# AM13E230x register map
Vendor: Texas Instruments; File version: Revised: 2025-12-26 17:30:06
CPU: CM33 r0p0, little endian, MPU, FPU, 4 interrupt priority bits
Registers are 32-bit, read-write, reset 0x0 unless marked. A register's access mark holds for its fields unless they carry their own. Offsets are from the block's base; [hi:lo] are bit positions; lines under a group give offsets from that group; {n}, {i} and the like mark numbered series; 'fields as' and 'values as' point back to an identical list.

## MCAN — PERIPHERALREGION
Base 0x40110000
{0x6004+8i} PINCM[{i}] (i=0..0) group
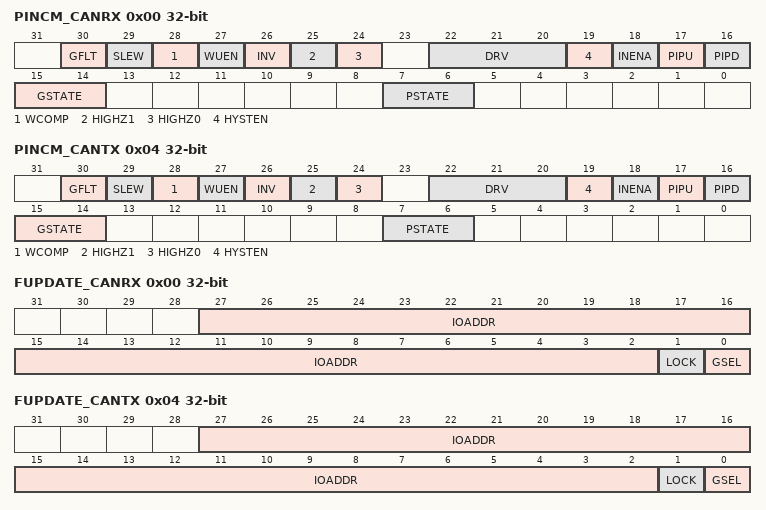
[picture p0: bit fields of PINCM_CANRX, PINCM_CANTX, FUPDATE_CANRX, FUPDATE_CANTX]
  0x00 PINCM_CANRX — CAN RX IO
    [30] GFLT — Glitch Filter Enable
      0=DISABLE (No internal glitch filter); 1=ENABLE (Use internal glitch filter)
    [29] SLEW — Reserved Slew Rate Control
      0=DISABLE (No Slew Rate Control); 1=ENABLE (Use Slew Rate Control)
    [28] WCOMP — Wake up compare value
      0=MATCH_ZERO (Match 0 will wake); 1=MATCH_ONE (Match 1 will wake)
    [27] WUEN — Wake up enable
      0=NO_WAKEUP (Wake up not enabled); 1=WAKEUP (Wake up enabled)
    [26] INV — Invert digital input/output relative to peripheral/GPIO
      0=NO_CHNG (Input and output are non-inverted); 1=CHNG (Input and output are inverted)
    [25] HIGHZ1 — High-Z instead of high output
      0=DRV_HIGH (Pin can be driven high); 1=DRV_HIZ (Pin is tri-stated instead of driven high)
    [24] HIGHZ0 — High-Z instead of low output
      0=DRV_LOW (Pin can be driven low); 1=DRV_HIZ (Pin is tri-stated instead of driven low)
    [22:20] DRV — Drive strength options
      0=STRENGTH_0 (Lowest drive strength); {v}=STRENGTH_{v} (Drive strength {v+1}/8) (v=1..6); 7=STRENGTH_7 (Highest drive strength)
    [19] HYSTEN — Hysteresis enable
      0=DIS_HYST (No hysteresis); 1=EN_HYST (Hysteresis on)
    [18] INENA — Input enable
      0=INP_DISABLE (Inputs 0 to connected core); 1=INP_ENABLE (Inputs IO pad value to connected core)
    [17] PIPU — Pull up enable
      0=NO_PULL_UP; 1=PULL_UP
    [16] PIPD — Pull down enable
      0=NO_PULL_DOWN; 1=PULL_DOWN
    [15:14] GSTATE — GPIO Channel State
      0=UNASSIGNED (G-Channel is in Unassigned State); 1=HANDOVER (G-Channel is in Handover State); 2=CONC_NOT_LOCKED (G-Channel is in Connected State and not Locked (That is F field is allowed to change without going back through Unassigned state)); 3=CONC_LOCKED (G-Channel is in Connected State and Locked (That is F field is not allowed to change to a different non-Zero value until both G and P channels go to Unassigned))
    [7:6] PSTATE — Peripheral-Analog Channel State
      0=UNASSIGNED (P-Channel is in Unassigned State); 1=HANDOVER (P-Channel is in Handover State); 2=CONC_NOT_LOCKED (P-Channel is in Connected State and not Locked (That is F field is allowed to change without going back through Unassigned state)); 3=CONC_LOCKED (P-Channel is in Connected State and Locked (That is F field is not allowed to change to a different non-Zero value until both G and P channels go to Unassigned))
  0x04 PINCM_CANTX — CAN TX IO
    fields as PINCM[0].PINCM_CANRX
{0x6204+8i} FUPDATE[{i}] (i=0..0) group
  0x00 FUPDATE_CANRX — FUPDATE version of CANRX
    [27:2] IOADDR wo — IO Address. This is the address that corresponds to the SOC address[27:2] of the module IP instance specific IO signal in the Full Write subregion of the pinmux subregion.
    [1] LOCK wo — Sets lock bit
      0=NOEFFECT (Writing this value has no effect); 1=LOCK (Set channel lock bit)
    [0] GSEL wo — GPIO channel Select 0: Select the P-Channel for the F update 1: Select the G-Channel for the F update
      0=PCHAN (Select the P-Channel for the F update); 1=GCHAN (Select the G-Channel for the F update)
  0x04 FUPDATE_CANTX — FUPDATE version of CANTX
    fields as FUPDATE[0].FUPDATE_CANRX
0x6480 CPU_CONNECT_0 — CPU Connect
0x6800 PWREN — Power enable
  [0] ENABLE — Power Enable
    0=DISABLE (Disable Power); 1=ENABLE (Enable Power)
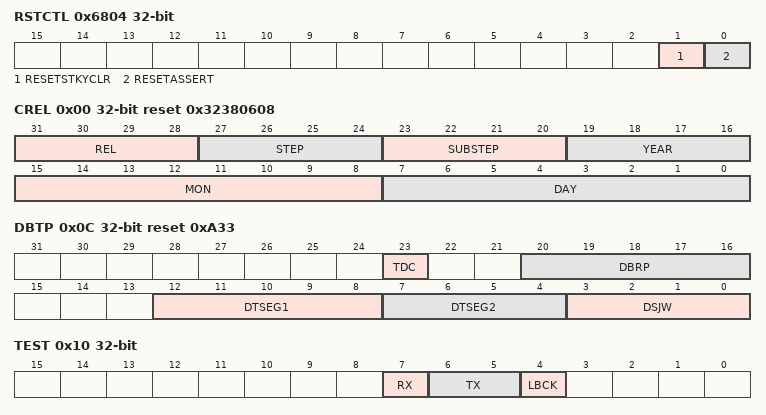
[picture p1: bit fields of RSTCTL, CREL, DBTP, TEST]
0x6804 RSTCTL wo — Reset Control
  [1] RESETSTKYCLR — Reset sticky bit clear
    0=NOP (Writing 0 has no effect); 1=CLR (Clear reset sticky bit)
  [0] RESETASSERT — Reset assertion to the peripheral
    0=NOP (Writing 0 has no effect); 1=ASSERT (Assert reset)
0x6814 STAT ro — Status Register
  [16] RESETSTKY — Reset sticky bit
    0=NORES (The peripheral has not been reset since this bit was last cleared by RESETSTKYCLR in the RSTCTL register); 1=RESET (The peripheral was reset since the last bit clear)
{0x7000+0xFC*i} MCAN[{i}] (i=0..0) group
  0x00 CREL ro reset 0x32380608 — MCAN Core Release Register
    [31:28] REL — Core Release
    [27:24] STEP — Step of Core Release
    [23:20] SUBSTEP — Sub-Step of Core Release
    [19:16] YEAR — Time Stamp Year
    [15:8] MON — Time Stamp Month
    [7:0] DAY — Time Stamp Day
  0x04 ENDN ro reset 0x87654321 — MCAN Endian Register
  0x0C DBTP reset 0xA33 — MCAN Data Bit Timing and Prescaler Register
    [23] TDC — Transmitter Delay Compensation
    [20:16] DBRP — Data Bit Rate Prescaler
    [12:8] DTSEG1 — Data Time Segment Before Sample Point
    [7:4] DTSEG2 — Data Time Segment After Sample Point
    [3:0] DSJW — Data Resynchronization Jump Width
  0x10 TEST (reset mask 0xFFFFFF7F) — MCAN Test Register
    [7] RX ro — Receive Pin
      0=DOMINANT (The CAN bus is dominant (CAN RX pin = '0')); 1=RECESSIVE (The CAN bus is recessive (CAN RX pin = '1'))
    [6:5] TX — Control of Transmit Pin
    [4] LBCK — Loop Back Mode
      0=DISABLE (Reset value, Loop Back Mode is disabled); 1=ENABLE (Loop Back Mode is enabled)
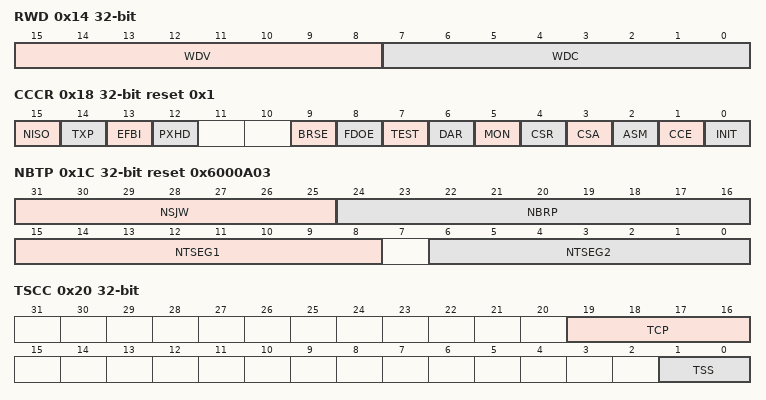
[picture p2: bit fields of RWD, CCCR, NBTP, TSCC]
  0x14 RWD — MCAN RAM Watchdog
    [15:8] WDV ro — Watchdog Value
    [7:0] WDC — Watchdog Configuration
  0x18 CCCR reset 0x1 — MCAN CC Control Register
    [15] NISO — Non-ISO Operation
    [14] TXP — Transmit Pause
    [13] EFBI — Edge Filtering During Bus Integration
    [12] PXHD — Protocol Exception Handling Disable
    [9] BRSE — Bit Rate Switch Enable
    [8] FDOE — Flexible Datarate Operation Enable
    [7] TEST — Test Mode Enable
    [6] DAR — Disable Automatic Retransmission
    [5] MON — Bus Monitoring Mode
    [4] CSR — Clock Stop Request
    [3] CSA ro — Clock Stop Acknowledge
    [2] ASM — Restricted Operation Mode
    [1] CCE — Configuration Change Enable
    [0] INIT — Initialization
  0x1C NBTP reset 0x6000A03 — MCAN Nominal Bit Timing and Prescaler Register
    [31:25] NSJW — Nominal (Re)Synchronization Jump Width
    [24:16] NBRP — Nominal Bit Rate Prescaler
    [15:8] NTSEG1 — Nominal Time Segment Before Sample Point
    [6:0] NTSEG2 — Nominal Time Segment After Sample Point
  0x20 TSCC — MCAN Timestamp Counter Configuration
    [19:16] TCP — Timestamp Counter Prescaler
    [1:0] TSS — Timestamp Select
  0x24 TSCV — MCAN Timestamp Counter Value
    [15:0] TSC — Timestamp Counter
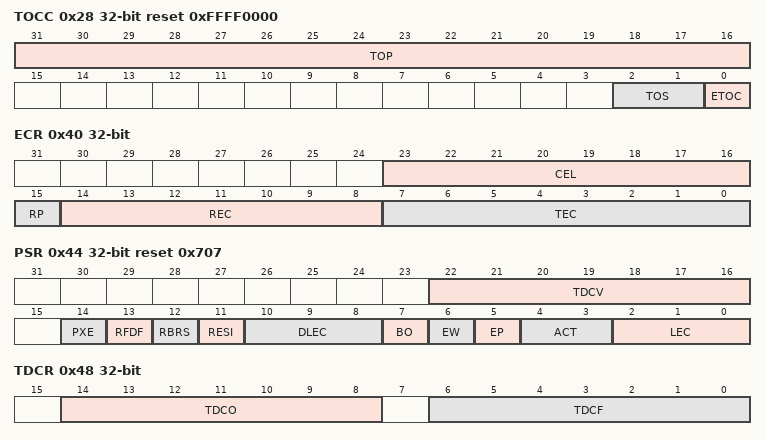
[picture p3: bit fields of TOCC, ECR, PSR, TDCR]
  0x28 TOCC reset 0xFFFF0000 — MCAN Timeout Counter Configuration
    [31:16] TOP — Timeout Period
    [2:1] TOS — Timeout Select
    [0] ETOC — Enable Timeout Counter
  0x2C TOCV reset 0xFFFF — MCAN Timeout Counter Value
    [15:0] TOC — Timeout Counter
  0x40 ECR ro — MCAN Error Counter Register
    [23:16] CEL — CAN Error Logging
    [15] RP — Receive Error Passive
    [14:8] REC — Receive Error Counter
    [7:0] TEC — Transmit Error Counter
  0x44 PSR ro reset 0x707 — MCAN Protocol Status Register
    [22:16] TDCV — Transmitter Delay Compensation Value
    [14] PXE — Protocol Exception Event
    [13] RFDF — Received a CAN FD Message
    [12] RBRS — BRS Flag of Last Received CAN FD Message
    [11] RESI — ESI Flag of Last Received CAN FD Message
    [10:8] DLEC — Data Phase Last Error Code
    [7] BO — Bus_Off Status
    [6] EW — Warning Status
    [5] EP — Error Passive
    [4:3] ACT — Node Activity
    [2:0] LEC — Last Error Code
  0x48 TDCR — MCAN Transmitter Delay Compensation Register
    [14:8] TDCO — Transmitter Delay Compensation Offset
    [6:0] TDCF — Transmitter Delay Compensation Filter Window Length
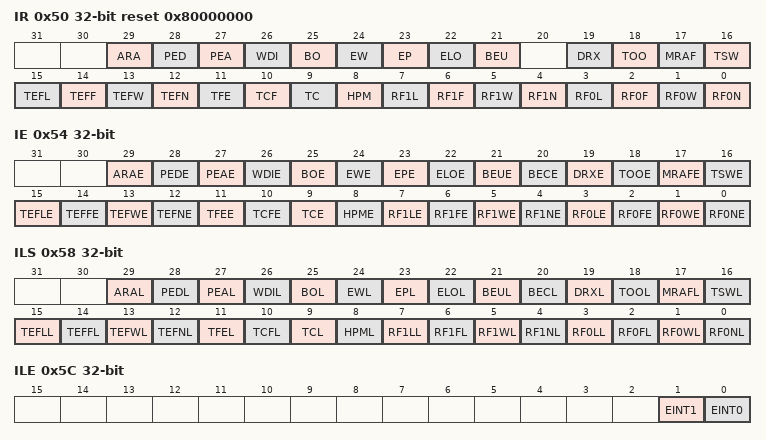
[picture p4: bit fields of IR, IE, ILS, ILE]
  0x50 IR reset 0x80000000 — MCAN Interrupt Register
    [29] ARA — Access to Reserved Address
    [28] PED — Protocol Error in Data Phase
    [27] PEA — Protocol Error in Arbitration Phase
    [26] WDI — Watchdog Interrupt
    [25] BO — Bus_Off Status
    [24] EW — Warning Status
    [23] EP — Error Passive
    [22] ELO — Error Logging Overflow
    [21] BEU — Bit Error Uncorrected
    [19] DRX — Message Stored to Dedicated Rx Buffer
    [18] TOO — Timeout Occurred
    [17] MRAF — Message RAM Access Failure
    [16] TSW — Timestamp Wraparound
    [15] TEFL — Tx Event FIFO Element Lost
    [14] TEFF — Tx Event FIFO Full
    [13] TEFW — Tx Event FIFO Watermark Reached
    [12] TEFN — Tx Event FIFO New Entry
    [11] TFE — Tx FIFO Empty
    [10] TCF — Transmission Cancellation Finished
    [9] TC — Transmission Completed
    [8] HPM — High Priority Message
    [7] RF1L — Rx FIFO 1 Message Lost
    [6] RF1F — Rx FIFO 1 Full
    [5] RF1W — Rx FIFO 1 Watermark Reached
    [4] RF1N — Rx FIFO 1 New Message
    [3] RF0L — Rx FIFO 0 Message Lost
    [2] RF0F — Rx FIFO 0 Full
    [1] RF0W — Rx FIFO 0 Watermark Reached
    [0] RF0N — Rx FIFO 0 New Message
  0x54 IE — MCAN Interrupt Enable
    [29] ARAE — Access to Reserved Address Enable
    [28] PEDE — Protocol Error in Data Phase Enable
    [27] PEAE — Protocol Error in Arbitration Phase Enable
    [26] WDIE — Watchdog Interrupt Enable
    [25] BOE — Bus_Off Status Enable
    [24] EWE — Warning Status Enable
    [23] EPE — Error Passive Enable
    [22] ELOE — Error Logging Overflow Enable
    [21] BEUE — Bit Error Uncorrected Enable
    [20] BECE — Bit Error Corrected Enable
    [19] DRXE — Message Stored to Dedicated Rx Buffer Enable
    [18] TOOE — Timeout Occurred Enable
    [17] MRAFE — Message RAM Access Failure Enable
    [16] TSWE — Timestamp Wraparound Enable
    [15] TEFLE — Tx Event FIFO Element Lost Enable
    [14] TEFFE — Tx Event FIFO Full Enable
    [13] TEFWE — Tx Event FIFO Watermark Reached Enable
    [12] TEFNE — Tx Event FIFO New Entry Enable
    [11] TFEE — Tx FIFO Empty Enable
    [10] TCFE — Transmission Cancellation Finished Enable
    [9] TCE — Transmission Completed Enable
    [8] HPME — High Priority Message Enable
    [7] RF1LE — Rx FIFO 1 Message Lost Enable
    [6] RF1FE — Rx FIFO 1 Full Enable
    [5] RF1WE — Rx FIFO 1 Watermark Reached Enable
    [4] RF1NE — Rx FIFO 1 New Message Enable
    [3] RF0LE — Rx FIFO 0 Message Lost Enable
    [2] RF0FE — Rx FIFO 0 Full Enable
    [1] RF0WE — Rx FIFO 0 Watermark Reached Enable
    [0] RF0NE — Rx FIFO 0 New Message Enable
  0x58 ILS — MCAN Interrupt Line Select
    [29] ARAL — Access to Reserved Address Line
    [28] PEDL — Protocol Error in Data Phase Line
    [27] PEAL — Protocol Error in Arbitration Phase Line
    [26] WDIL — Watchdog Interrupt Line
    [25] BOL — Bus_Off Status Line
    [24] EWL — Warning Status Line
    [23] EPL — Error Passive Line
    [22] ELOL — Error Logging Overflow Line
    [21] BEUL — Bit Error Uncorrected Line
    [20] BECL — Bit Error Corrected Line
    [19] DRXL — Message Stored to Dedicated Rx Buffer Line
    [18] TOOL — Timeout Occurred Line
    [17] MRAFL — Message RAM Access Failure Line
    [16] TSWL — Timestamp Wraparound Line
    [15] TEFLL — Tx Event FIFO Element Lost Line
    [14] TEFFL — Tx Event FIFO Full Line
    [13] TEFWL — Tx Event FIFO Watermark Reached Line
    [12] TEFNL — Tx Event FIFO New Entry Line
    [11] TFEL — Tx FIFO Empty Line
    [10] TCFL — Transmission Cancellation Finished Line
    [9] TCL — Transmission Completed Line
    [8] HPML — High Priority Message Line
    [7] RF1LL — Rx FIFO 1 Message Lost Line
    [6] RF1FL — Rx FIFO 1 Full Line
    [5] RF1WL — Rx FIFO 1 Watermark Reached Line
    [4] RF1NL — Rx FIFO 1 New Message Line
    [3] RF0LL — Rx FIFO 0 Message Lost Line
    [2] RF0FL — Rx FIFO 0 Full Line
    [1] RF0WL — Rx FIFO 0 Watermark Reached Line
    [0] RF0NL — Rx FIFO 0 New Message Line
  0x5C ILE — MCAN Interrupt Line Enable
    [1] EINT1 — Enable Interrupt Line 1
    [0] EINT0 — Enable Interrupt Line 0
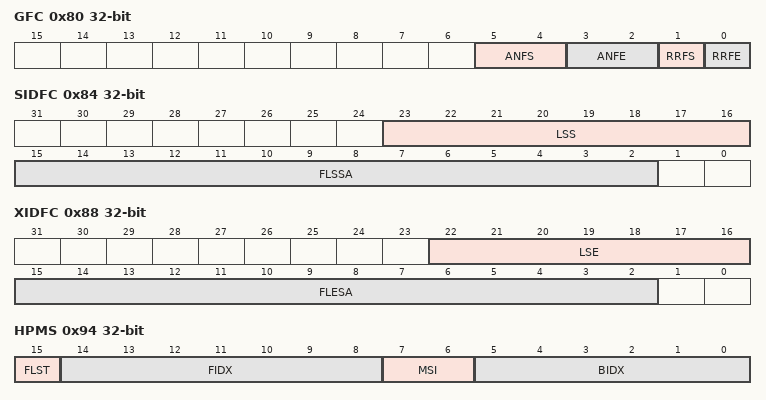
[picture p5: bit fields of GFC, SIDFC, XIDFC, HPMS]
  0x80 GFC — MCAN Global Filter Configuration
    [5:4] ANFS — Accept Non-matching Frames Standard
    [3:2] ANFE — Accept Non-matching Frames Extended
    [1] RRFS — Reject Remote Frames Standard
    [0] RRFE — Reject Remote Frames Extended
  0x84 SIDFC — MCAN Standard ID Filter Configuration
    [23:16] LSS — List Size Standard
    [15:2] FLSSA — Filter List Standard Start Address
  0x88 XIDFC — MCAN Extended ID Filter Configuration
    [22:16] LSE — List Size Extended
    [15:2] FLESA — Filter List Extended Start Address
  0x90 XIDAM reset 0x1FFFFFFF — MCAN Extended ID and Mask
    [28:0] EIDM — Extended ID Mask
  0x94 HPMS ro — MCAN High Priority Message Status
    [15] FLST — Filter List
    [14:8] FIDX — Filter Index
    [7:6] MSI — Message Storage Indicator
    [5:0] BIDX — Buffer Index
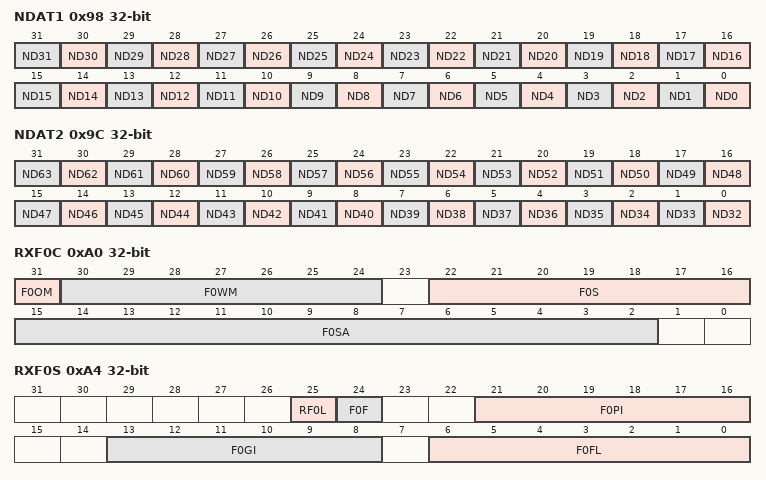
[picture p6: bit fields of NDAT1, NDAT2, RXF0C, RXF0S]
  0x98 NDAT1 — MCAN New Data 1
    [n] ND{n} (n=0..31) — New Data RX Buffer {n}
  0x9C NDAT2 — MCAN New Data 2
    [n-32] ND{n} (n=32..63) — New Data RX Buffer {n}
  0xA0 RXF0C — MCAN Rx FIFO 0 Configuration
    [31] F0OM — FIFO 0 Operation Mode
    [30:24] F0WM — Rx FIFO 0 Watermark
    [22:16] F0S — Rx FIFO 0 Size
    [15:2] F0SA — Rx FIFO 0 Start Address
  0xA4 RXF0S ro — MCAN Rx FIFO 0 Status
    [25] RF0L — Rx FIFO 0 Message Lost
    [24] F0F — Rx FIFO 0 Full
    [21:16] F0PI — Rx FIFO 0 Put Index
    [13:8] F0GI — Rx FIFO 0 Get Index
    [6:0] F0FL — Rx FIFO 0 Fill Level
  0xA8 RXF0A — MCAN Rx FIFO 0 Acknowledge
    [5:0] F0AI — Rx FIFO 0 Acknowledge Index
  0xAC RXBC — MCAN Rx Buffer Configuration
    [15:2] RBSA — Rx Buffer Start Address
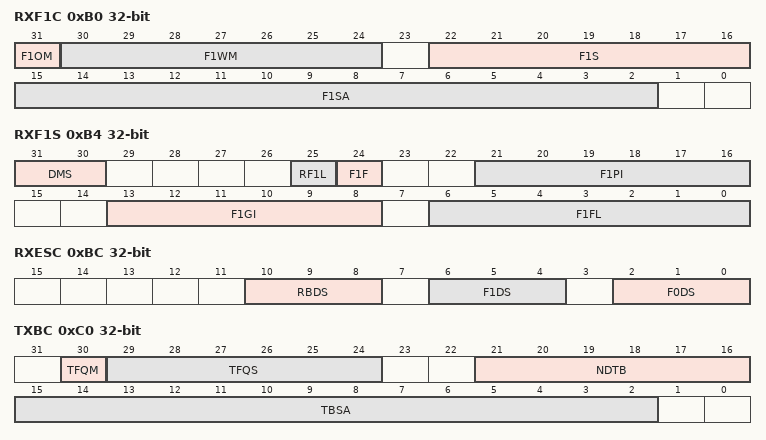
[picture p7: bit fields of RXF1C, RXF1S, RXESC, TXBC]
  0xB0 RXF1C — MCAN Rx FIFO 1 Configuration
    [31] F1OM — FIFO 1 Operation Mode
    [30:24] F1WM — Rx FIFO 1 Watermark
    [22:16] F1S — Rx FIFO 1 Size
    [15:2] F1SA — Rx FIFO 1 Start Address
  0xB4 RXF1S ro — MCAN Rx FIFO 1 Status
    [31:30] DMS — Debug Message Status
    [25] RF1L — Rx FIFO 1 Message Lost
    [24] F1F — Rx FIFO 1 Full
    [21:16] F1PI — Rx FIFO 1 Put Index
    [13:8] F1GI — Rx FIFO 1 Get Index
    [6:0] F1FL — Rx FIFO 1 Fill Level
  0xB8 RXF1A — MCAN Rx FIFO 1 Acknowledge
    [5:0] F1AI — Rx FIFO 1 Acknowledge Index
  0xBC RXESC — MCAN Rx Buffer / FIFO Element Size Configuration
    [10:8] RBDS — Rx Buffer Data Field Size
    [6:4] F1DS — Rx FIFO 1 Data Field Size
    [2:0] F0DS — Rx FIFO 0 Data Field Size
  0xC0 TXBC — MCAN Tx Buffer Configuration
    [30] TFQM — Tx FIFO/Queue Mode
    [29:24] TFQS — Transmit FIFO/Queue Size
    [21:16] NDTB — Number of Dedicated Transmit Buffers
    [15:2] TBSA — Tx Buffers Start Address
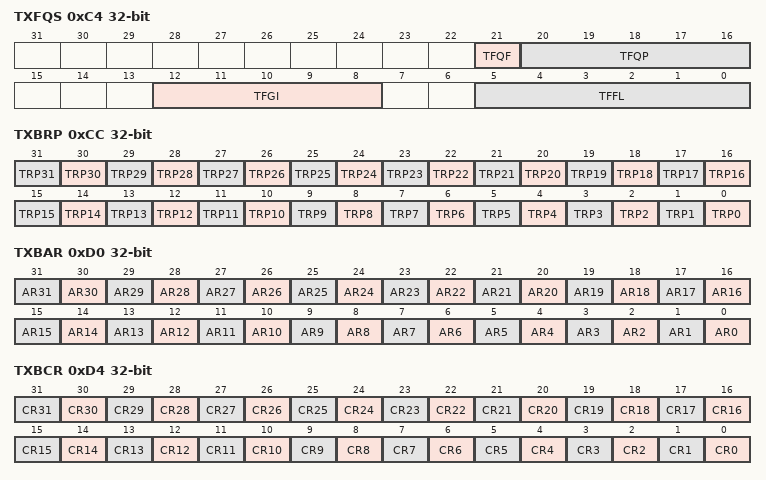
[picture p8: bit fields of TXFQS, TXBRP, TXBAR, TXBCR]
  0xC4 TXFQS ro — MCAN Tx FIFO / Queue Status
    [21] TFQF — Tx FIFO/Queue Full
    [20:16] TFQP — Tx FIFO/Queue Put Index
    [12:8] TFGI — Tx FIFO Get Index
    [5:0] TFFL — Tx FIFO Free Level
  0xC8 TXESC — MCAN Tx Buffer Element Size Configuration
    [2:0] TBDS — Tx Buffer Data Field Size
  0xCC TXBRP ro — MCAN Tx Buffer Request Pending
    [n] TRP{n} (n=0..31) — Transmission Request Pending {n}
  0xD0 TXBAR — MCAN Tx Buffer Add Request
    [n] AR{n} (n=0..31) — Add Request {n}
  0xD4 TXBCR — MCAN Tx Buffer Cancellation Request
    [n] CR{n} (n=0..31) — Cancellation Request {n}
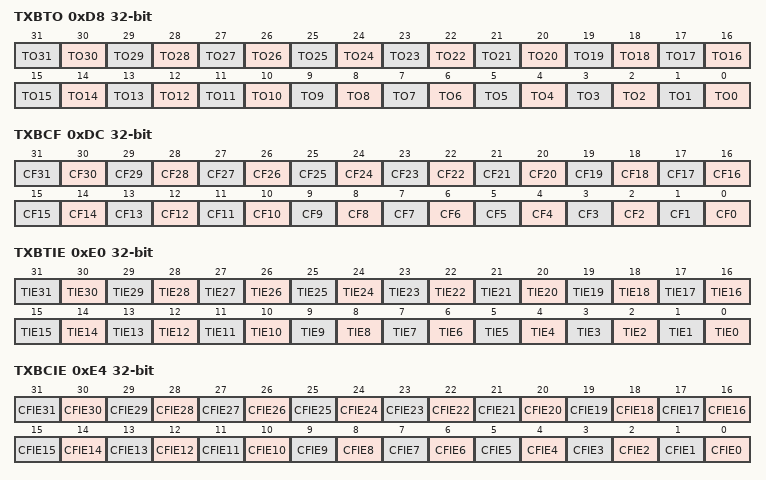
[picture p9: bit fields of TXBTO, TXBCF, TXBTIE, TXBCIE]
  0xD8 TXBTO ro — MCAN Tx Buffer Transmission Occurred
    [n] TO{n} (n=0..31) — Transmission Occurred {n}
  0xDC TXBCF ro — MCAN Tx Buffer Cancellation Finished
    [n] CF{n} (n=0..31) — Cancellation Finished {n}
  0xE0 TXBTIE — MCAN Tx Buffer Transmission Interrupt Enable
    [n] TIE{n} (n=0..31) — Transmission Interrupt Enable {n}
  0xE4 TXBCIE — MCAN Tx Buffer Cancellation Finished Interrupt Enable
    [n] CFIE{n} (n=0..31) — Cancellation Finished Interrupt Enable {n}
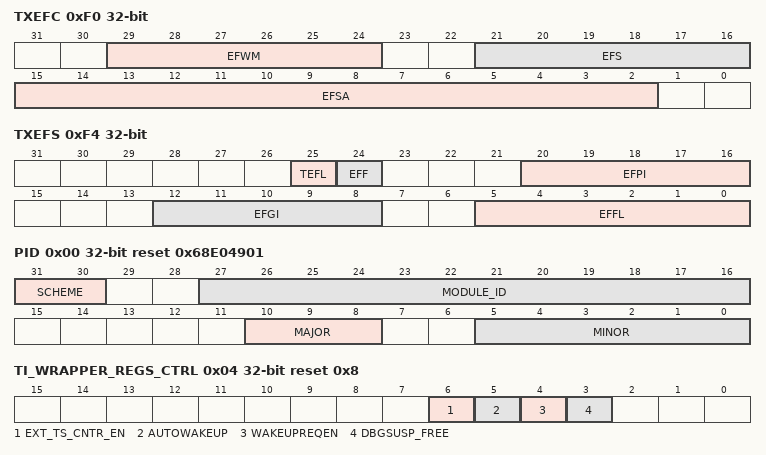
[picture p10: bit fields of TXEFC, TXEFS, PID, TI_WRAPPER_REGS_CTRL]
  0xF0 TXEFC — MCAN Tx Event FIFO Configuration
    [29:24] EFWM — Event FIFO Watermark
    [21:16] EFS — Event FIFO Size
    [15:2] EFSA — Event FIFO Start Address
  0xF4 TXEFS ro — MCAN Tx Event FIFO Status
    [25] TEFL — Tx Event FIFO Element Lost
    [24] EFF — Event FIFO Full
    [20:16] EFPI — Event FIFO Put Index
    [12:8] EFGI — Event FIFO Get Index
    [5:0] EFFL — Event FIFO Fill Level
  0xF8 TXEFA — MCAN Tx Event FIFO Acknowledge
    [4:0] EFAI — Event FIFO Acknowledge Index
{0x7200+0xA00*i} TI_WRAPPER[{i}] (i=0..0) group
  {0x0+0x410*j} PROCESSORS[{j}] (j=0..0) group
    {0x0+0x2C*k} REGS[{k}] (k=0..0) group
      0x00 PID ro reset 0x68E04901 — MCAN Subsystem Revision Register
        [31:30] SCHEME — PID Register Scheme
        [27:16] MODULE_ID — Module Identification Number
        [10:8] MAJOR — Major Revision
        [5:0] MINOR — Minor Revision
      0x04 TI_WRAPPER_REGS_CTRL reset 0x8 — MCAN Subsystem Control Register
        [6] EXT_TS_CNTR_EN — External Timestamp Counter Enable
        [5] AUTOWAKEUP — Automatic Wakeup Enable
        [4] WAKEUPREQEN — Wakeup Request Enable
        [3] DBGSUSP_FREE — Debug Suspend Free
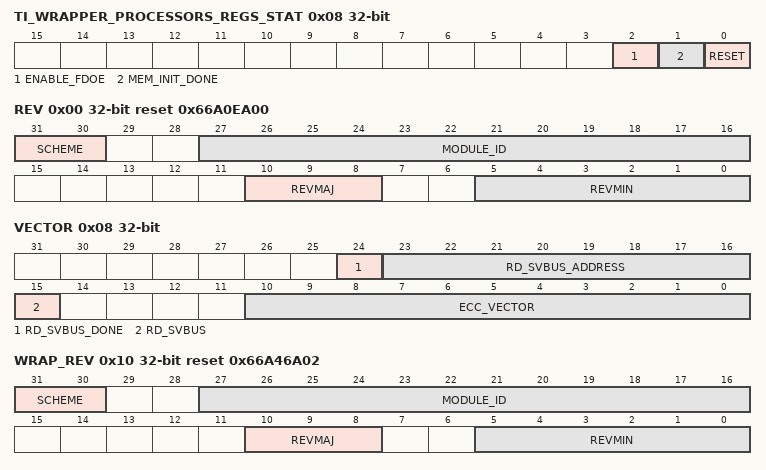
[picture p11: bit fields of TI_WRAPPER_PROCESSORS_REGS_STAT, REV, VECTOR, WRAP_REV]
      0x08 TI_WRAPPER_PROCESSORS_REGS_STAT ro (reset mask 0xFFFFFFFB) — MCAN Subsystem Status Register
        [2] ENABLE_FDOE — Flexible Datarate Operation Enable
        [1] MEM_INIT_DONE — Memory Initialization Done
        [0] RESET — Soft Reset Status
      0x0C ICS — MCAN Subsystem Interrupt Clear Shadow Register
        [0] EXT_TS_CNTR_OVFL — External Timestamp Counter Overflow Interrupt Status Clear
      0x10 IRS — MCAN Subsystem Interrupt Raw Satus Register
        [0] EXT_TS_CNTR_OVFL — External Timestamp Counter Overflow Interrupt Status
      0x14 IECS — MCAN Subsystem Interrupt Enable Clear Shadow Register
        [0] EXT_TS_CNTR_OVFL — External Timestamp Counter Overflow Interrupt Enable Clear
      0x18 TI_WRAPPER_PROCESSORS_REGS_IE — MCAN Subsystem Interrupt Enable Register
        [0] EXT_TS_CNTR_OVFL — External Timestamp Counter Overflow Interrupt Enable
      0x1C IES ro — MCAN Subsystem Interrupt Enable Status
        [0] EXT_TS_CNTR_OVFL — External Timestamp Counter Overflow Interrupt Enable Status
      0x20 EOI — MCAN Subsystem End of Interrupt
        [7:0] EOI — External Timestamp Counter Overflow End of Interrupt
      0x24 EXT_TS_PRESCALER — MCAN Subsystem External Timestamp Prescaler 0
        [23:0] PRESCALER — External Timestamp Prescaler
      0x28 EXT_TS_UNSERVICED_INTR_CNTR ro — MCAN Subsystem External Timestamp Unserviced Interrupts Counter
        [4:0] EXT_TS_INTR_CNTR — External Timestamp Counter Unserviced Rollover Interrupts
    {0x200+0x210*k} ECC_REGS[{k}] (k=0..0) group
      0x00 REV ro reset 0x66A0EA00 — MCAN Error Aggregator Revision Register
        [31:30] SCHEME — PID Register Scheme
        [27:16] MODULE_ID — Module Identification Number
        [10:8] REVMAJ — Major Revision
        [5:0] REVMIN — Minor Revision
      0x08 VECTOR — MCAN ECC Vector Register
        [24] RD_SVBUS_DONE ro — Read Completion Flag
        [23:16] RD_SVBUS_ADDRESS — Read Address Offset
        [15] RD_SVBUS — Read Trigger
        [10:0] ECC_VECTOR — ECC RAM ID
      0x0C TI_WRAPPER_PROCESSORS_ECC_REGS_STAT ro reset 0x2 — MCAN Error Misc Status
        [10:0] NUM_RAMS — Number of RAMs
      0x10 WRAP_REV ro reset 0x66A46A02 — MCAN ECC Wrapper Revision Register
        fields as TI_WRAPPER[0].PROCESSORS[0].ECC_REGS[0].REV
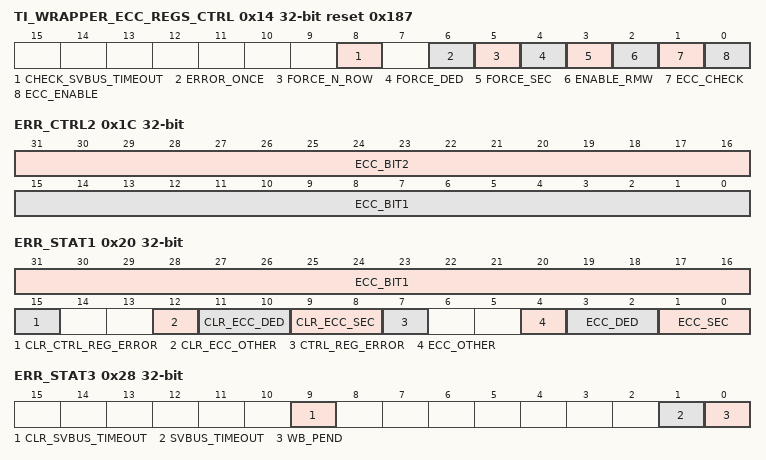
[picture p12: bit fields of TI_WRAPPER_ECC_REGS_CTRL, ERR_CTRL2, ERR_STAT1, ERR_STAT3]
      0x14 TI_WRAPPER_ECC_REGS_CTRL reset 0x187 — MCAN ECC Control
        [8] CHECK_SVBUS_TIMEOUT — SVBUS Timeout Enable
        [6] ERROR_ONCE — Force Error Only Once Enable
        [5] FORCE_N_ROW — Force Next Single/Double Bit Error
        [4] FORCE_DED — Force Double Bit Error Detected Error
        [3] FORCE_SEC — Force Single Bit Error Corrected Error
        [2] ENABLE_RMW — Enable Read-Modify-Write
        [1] ECC_CHECK — Enable ECC Check
        [0] ECC_ENABLE — Enable ECC Generation
      0x18 ERR_CTRL1 — MCAN ECC Error Control 1 Register
      0x1C ERR_CTRL2 — MCAN ECC Error Control 2 Register
        [31:16] ECC_BIT2 — Force Error Bit2 Column Index
        [15:0] ECC_BIT1 — Force Error Bit1 Column Index
      0x20 ERR_STAT1 — MCAN ECC Error Status 1 Register
        [31:16] ECC_BIT1 ro — ECC Error Bit Position
        [15] CLR_CTRL_REG_ERROR — Clear Control Register Error
        [12] CLR_ECC_OTHER — Clear ECC_OTHER
        [11:10] CLR_ECC_DED — Clear ECC_DED
        [9:8] CLR_ECC_SEC — Clear ECC_SEC
        [7] CTRL_REG_ERROR — Control Register Error
        [4] ECC_OTHER — SEC While Writeback Error Status
        [3:2] ECC_DED — Double Bit Error Detected Status
        [1:0] ECC_SEC — Single Bit Error Corrected Status
      0x24 ERR_STAT2 ro — MCAN ECC Error Status 2 Register
      0x28 ERR_STAT3 — MCAN ECC Error Status 3 Register
        [9] CLR_SVBUS_TIMEOUT — Clear Serial VBUS Timeout
        [1] SVBUS_TIMEOUT — Serial VBUS Timeout Flag
        [0] WB_PEND ro — Delayed Write Back Pending Status
      0x3C SEC_EOI — MCAN Single Error Corrected End of Interrupt Register
        [0] EOI_WR — End of Interrupt
      0x40 SEC_STATUS — MCAN Single Error Corrected Interrupt Status Register
        [0] MSGMEM_PEND ro — Message RAM SEC Interrupt Pending
      0x80 SEC_ENABLE_SET — MCAN Single Error Corrected Interrupt Enable Set Register
        [0] MSGMEM_ENABLE_SET — Message RAM SEC Interrupt Pending Enable Set
      0xC0 SEC_ENABLE_CLR — MCAN Single Error Corrected Interrupt Enable Clear Register
        [0] MSGMEM_ENABLE_CLR — Message RAM SEC Interrupt Pending Enable Clear
      0x13C DED_EOI — MCAN Double Error Detected End of Interrupt Register
        [0] EOI_WR — End of Interrupt
      0x140 DED_STATUS — MCAN Double Error Detected Interrupt Status Register
        [0] MSGMEM_PEND ro — Message RAM DED Interrupt Pending
      0x180 DED_ENABLE_SET — MCAN Double Error Detected Interrupt Enable Set Register
        [0] MSGMEM_ENABLE_SET — Message RAM DED Interrupt Pending Enable Set
      0x1C0 DED_ENABLE_CLR — MCAN Double Error Detected Interrupt Enable Clear Register
        [0] MSGMEM_ENABLE_CLR — Message RAM DED Interrupt Pending Enable Clear
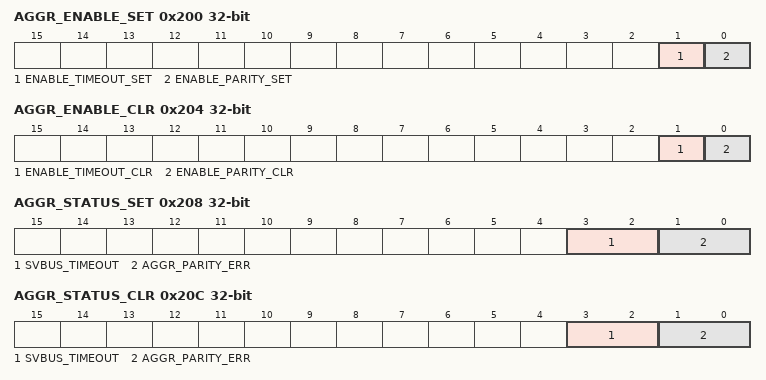
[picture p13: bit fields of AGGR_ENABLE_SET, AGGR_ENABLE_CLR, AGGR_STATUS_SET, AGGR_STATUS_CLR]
      0x200 AGGR_ENABLE_SET — MCAN Error Aggregator Enable Set Register
        [1] ENABLE_TIMEOUT_SET — Enable Timeout Errors Set
        [0] ENABLE_PARITY_SET — Enable Parity Errors Set
      0x204 AGGR_ENABLE_CLR — MCAN Error Aggregator Enable Clear Register
        [1] ENABLE_TIMEOUT_CLR — Enable Timeout Errors Clear
        [0] ENABLE_PARITY_CLR — Enable Parity Errors Clear
      0x208 AGGR_STATUS_SET — MCAN Error Aggregator Status Set Register
        [3:2] SVBUS_TIMEOUT — Aggregator Serial VBUS Timeout Error Status
        [1:0] AGGR_PARITY_ERR — Aggregator Parity Error Status
      0x20C AGGR_STATUS_CLR — MCAN Error Aggregator Status Clear Register
        fields as TI_WRAPPER[0].PROCESSORS[0].ECC_REGS[0].AGGR_STATUS_SET
  {0x600+0x200*j} MSP[{j}] (j=0..0) group
    {0x20+0x2C*k} CPU_INT[{k}] (k=0..0) group
      0x00 IIDX ro — Interrupt Index Register
        [7:0] STAT — Interrupt index status
          0=NO_INTR (No interrupt pending.); 1=INTL0 (MCAN Interrupt Line 0 interrupt pending.); 2=INTL1 (MCAN Interrupt Line 1 interrupt pending.); 3=SEC (Message RAM SEC (Single Error Correction) interrupt pending.); 4=DED (Message RAM DED (Double Error Detection) interrupt pending.); 5=EXT_TS_CNTR_OVFL (External Timestamp Counter Overflow interrupt pending.); 6=WAKEUP (Clock Stop Wake Up interrupt pending.)
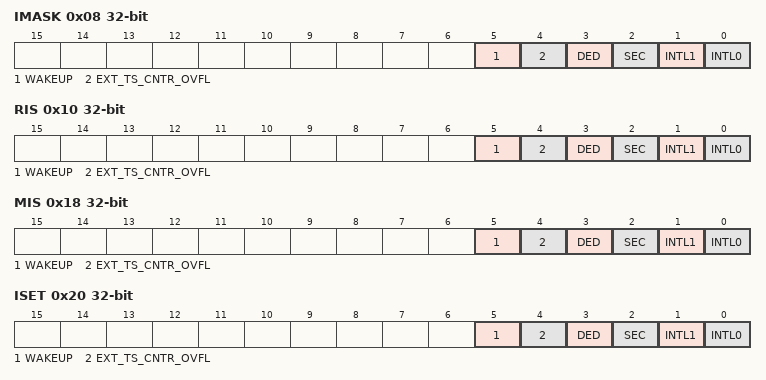
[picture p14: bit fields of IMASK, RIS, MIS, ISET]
      0x08 IMASK — Interrupt mask
        [all] fields
          0=CLR (Clear Interrupt Mask); 1=SET (Set Interrrupt Mask)
        [5] WAKEUP — Clock Stop Wake Up Interrupt
        [4] EXT_TS_CNTR_OVFL — External Timestamp Counter Overflow
        [3] DED — Message RAM DED interrupt
        [2] SEC — Message RAM SEC interrupt
        [1] INTL1 — MCAN Interrupt Line 1
        [0] INTL0 — MCAN Interrupt Line 0
      0x10 RIS ro — Raw interrupt status
        [all] fields
          0=CLR (Interrupt did not occur); 1=SET (Interrupt occured)
        [5] WAKEUP — Clock Stop Wake Up Interrupt
        [4] EXT_TS_CNTR_OVFL — External Timestamp Counter Overflow Interrupt
        [3] DED — Message RAM DED interrupt
        [2] SEC — Message RAM SEC interrupt
        [1] INTL1 — MCAN Interrupt Line 1
        [0] INTL0 — MCAN Interrupt Line 0
      0x18 MIS ro — Masked interrupt status
        fields as TI_WRAPPER[0].MSP[0].CPU_INT[0].RIS
      0x20 ISET wo — Interrupt set
        [all] fields
          0=NO_EFFECT (Writing 0 has no effect); 1=SET (Set Interrupt)
        [5] WAKEUP — Clock Stop Wake Up Interrupt
        [4] EXT_TS_CNTR_OVFL — External Timestamp Counter Overflow Iterrupt
        [3] DED — Message RAM DED interrupt
        [2] SEC — Message RAM SEC interrupt
        [1] INTL1 — MCAN Interrupt Line 1
        [0] INTL0 — MCAN Interrupt Line 0
      0x28 ICLR wo — Interrupt clear
        [all] fields
          0=NO_EFFECT (Writing 0 has no effect); 1=CLR (Clear Interrupt)
        [5] WAKEUP — Clock Stop Wake Up Interrupt
        [4] EXT_TS_CNTR_OVFL — External Timestamp Counter Overflow Interrupt
        [3] DED — Message RAM DED interrupt
        [2] SEC — Message RAM SEC interrupt
        [1] INTL1 — MCAN Interrupt Line 1
        [0] INTL0 — MCAN Interrupt Line 0
    0xE0 EVT_MODE — Event Mode
      [1:0] INT0_CFG ro — Event line mode select for event corresponding to [IPSTANDARD.CPU_INT]
        0=DISABLE (The interrupt or event line is disabled.); 1=SOFTWARE (The interrupt or event line is in software mode. Software must clear the RIS.); 2=HARDWARE (The interrupt or event line is in hardware mode. The hardware (another module) clears automatically the associated RIS flag.)
    0xFC DESC ro — Module Description
      [31:16] MODULEID — Module identification contains a unique peripheral identification number. The assignments are maintained in a central database for all of the platform modules to ensure uniqueness.
      [15:12] FEATUREVER — Feature Set for the module *instance*
        0=VERSION_0 (MCAN module with CAN-FD mode enabled); 1=VERSION_1 (MCAN module with CAN-FD mode disabled)
      [7:4] MAJREV — Major rev of the IP
      [3:0] MINREV — Minor rev of the IP
    0x100 CLKEN — MCAN module clock enable
      [0] CLK_REQEN — MCAN clock request enable
        0=CLR (MCAN module functional clock and Vbusp is not requested. These clocks are gated to the MCAN module.); 1=SET (Setting this bit requests MCAN module functional clock and Vbusp. These clocks are not gated to MCAN module.)
    0x104 CLKDIV — Clock divider
      [1:0] RATIO — MCAN functional clock divide settings
        0=DIV_BY_1_ (Divides input clock by 1); 1=DIV_BY_2_ (Divides input clock by 2); 2=DIV_BY_4_ (Divides input clock by 4); 3=DIV_BY_1_1 (Divides input clock by 1)
    0x108 CLKCTL — MCAN-SS clock stop control register
      [8] WKUP_GLTFLT_EN — Clock stop wake-up on RXD, glitch filter enable.
        0=DISABLE (Disable glitch filter enable on RXD input when MCAN is in clock stop mode (waiting for event on RXD input for clock stop wakeup).); 1=ENABLE (Enable glitch filter enable on RXD input when MCAN is in clock stop mode (waiting for event on RXD input for clock stop wakeup).)
      [4] WAKEUP_INT_EN — MCAN IP clock stop wakeup interrupt enable bit
        0=DISABLE (Disable MCAN IP clock stop wakeup interrupt); 1=ENABLE (Enable MCAN IP clock stop wakeup interrupt)
      [0] STOPREQ — MCAN clock stop request bit
        0=DISABLE (Disable MCAN-SS clock stop request); 1=ENABLE (Enable MCAN-SS clock stop request)
    0x10C CLKSTS ro — MCANSS clock stop status register
      [8] CCLKDONE — MCAN controller clock request status from GPRCM
        0=RESET (MCAN controller clock is not available to the MCAN IP.); 1=SET (MCAN controller clock is enabled and available to the MCAN IP.)
      [4] STOPREQ_HW_OVR — MCANSS clock stop HW override status bit
        0=RESET (MCANSS_CLKCTL.STOPREQ bit has not been cleared by HW.); 1=SET (MCANSS_CLKCTL.STOPREQ bit has been cleared by HW.)
      [0] CLKSTOP_ACKSTS — Clock stop acknowledge status from MCAN IP
        0=RESET (No clock stop acknowledged.); 1=SET (Clock stop has been acknowledged by MCAN IP; MCAN-SS may be clock gated by stopping both the CAN host and functional clocks.)
